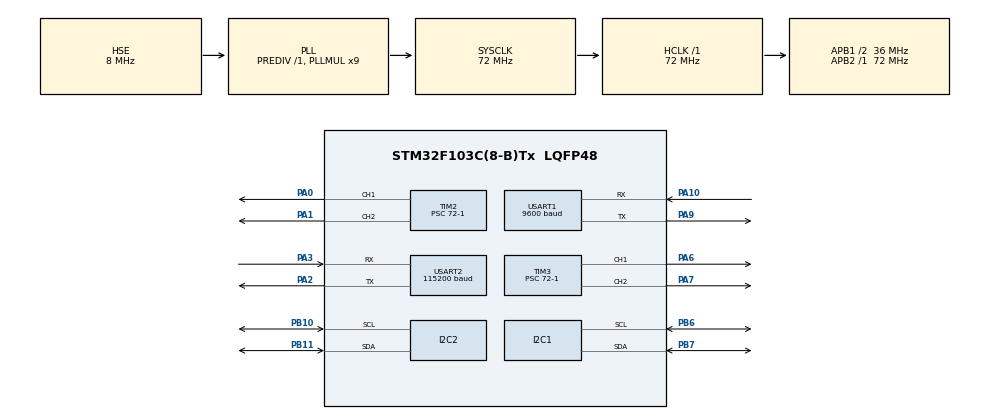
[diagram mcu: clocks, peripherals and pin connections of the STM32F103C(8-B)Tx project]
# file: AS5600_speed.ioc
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Dma.I2C1_RX.0.Direction=DMA_PERIPH_TO_MEMORY
Dma.I2C1_RX.0.Instance=DMA1_Channel7
Dma.I2C1_RX.0.MemDataAlignment=DMA_MDATAALIGN_BYTE
Dma.I2C1_RX.0.MemInc=DMA_MINC_ENABLE
Dma.I2C1_RX.0.Mode=DMA_NORMAL
Dma.I2C1_RX.0.PeriphDataAlignment=DMA_PDATAALIGN_BYTE
Dma.I2C1_RX.0.PeriphInc=DMA_PINC_DISABLE
Dma.I2C1_RX.0.Priority=DMA_PRIORITY_LOW
Dma.I2C2_RX.1.Direction=DMA_PERIPH_TO_MEMORY
Dma.I2C2_RX.1.Instance=DMA1_Channel5
Dma.I2C2_RX.1.MemDataAlignment=DMA_MDATAALIGN_BYTE
Dma.I2C2_RX.1.MemInc=DMA_MINC_ENABLE
Dma.I2C2_RX.1.Mode=DMA_NORMAL
Dma.I2C2_RX.1.PeriphDataAlignment=DMA_PDATAALIGN_BYTE
Dma.I2C2_RX.1.PeriphInc=DMA_PINC_DISABLE
Dma.I2C2_RX.1.Priority=DMA_PRIORITY_LOW
Dma.Request0=I2C1_RX
Dma.Request1=I2C2_RX
FREERTOS.Tasks01=defaultTask,0,128,StartDefaultTask,As weak,NULL,Dynamic,NULL,NULL;myTask02,0,128,Motor_Task,As weak,NULL,Dynamic,NULL,NULL
I2C1.I2C_Mode=I2C_Fast
I2C2.I2C_Mode=I2C_Fast
Mcu.Family=STM32F1
Mcu.Name=STM32F103C(8-B)Tx
Mcu.Package=LQFP48
NVIC.DMA1_Channel5_IRQn=true\:5\:0\:false\:false\:true\:true\:false\:true\:true
NVIC.DMA1_Channel7_IRQn=true\:5\:0\:false\:false\:true\:true\:false\:true\:true
NVIC.PriorityGroup=NVIC_PRIORITYGROUP_4
NVIC.TIM4_IRQn=true\:5\:0\:false\:false\:true\:true\:true\:true\:true
NVIC.USART1_IRQn=true\:5\:0\:false\:false\:true\:true\:true\:true\:true
NVIC.USART2_IRQn=true\:5\:0\:false\:false\:true\:true\:true\:true\:true
PA0-WKUP.Signal=S_TIM2_CH1_ETR
PA1.Signal=S_TIM2_CH2
PA10.Mode=Asynchronous
PA10.Signal=USART1_RX
PA13.Mode=Serial_Wire
PA13.Signal=SYS_JTMS-SWDIO
PA14.Mode=Serial_Wire
PA14.Signal=SYS_JTCK-SWCLK
PA2.Mode=Asynchronous
PA2.Signal=USART2_TX
PA3.Mode=Asynchronous
PA3.Signal=USART2_RX
PA6.Signal=S_TIM3_CH1
PA7.Signal=S_TIM3_CH2
PA9.Mode=Asynchronous
PA9.Signal=USART1_TX
PB10.Mode=I2C
PB10.Signal=I2C2_SCL
PB11.Mode=I2C
PB11.Signal=I2C2_SDA
PB6.Mode=I2C
PB6.Signal=I2C1_SCL
PB7.Mode=I2C
PB7.Signal=I2C1_SDA
PD0-OSC_IN.Mode=HSE-External-Oscillator
PD0-OSC_IN.Signal=RCC_OSC_IN
PD1-OSC_OUT.Mode=HSE-External-Oscillator
PD1-OSC_OUT.Signal=RCC_OSC_OUT
ProjectManager.HeapSize=0x200
ProjectManager.StackSize=0x400
ProjectManager.TargetToolchain=MDK-ARM V5.32
RCC.AHBFreq_Value=72000000
RCC.APB1CLKDivider=RCC_HCLK_DIV2
RCC.APB1Freq_Value=36000000
RCC.APB1TimFreq_Value=72000000
RCC.APB2Freq_Value=72000000
RCC.APB2TimFreq_Value=72000000
RCC.HCLKFreq_Value=72000000
RCC.PLLMUL=RCC_PLL_MUL9
RCC.PLLSourceVirtual=RCC_PLLSOURCE_HSE
RCC.SYSCLKFreq_VALUE=72000000
RCC.SYSCLKSource=RCC_SYSCLKSOURCE_PLLCLK
RCC.USBFreq_Value=72000000
SH.S_TIM2_CH1_ETR.0=TIM2_CH1,PWM Generation1 CH1
SH.S_TIM2_CH2.0=TIM2_CH2,PWM Generation2 CH2
SH.S_TIM3_CH1.0=TIM3_CH1,PWM Generation1 CH1
SH.S_TIM3_CH2.0=TIM3_CH2,PWM Generation2 CH2
TIM2.Channel-PWM\ Generation1\ CH1=TIM_CHANNEL_1
TIM2.Channel-PWM\ Generation2\ CH2=TIM_CHANNEL_2
TIM2.Period=20000-1
TIM2.Prescaler=72-1
TIM3.Channel-PWM\ Generation1\ CH1=TIM_CHANNEL_1
TIM3.Channel-PWM\ Generation2\ CH2=TIM_CHANNEL_2
TIM3.Period=20000-1
TIM3.Prescaler=72-1
TIM4.Period=10-1
TIM4.Prescaler=7200-1
USART1.BaudRate=9600
USART1.VirtualMode=VM_ASYNC
USART2.BaudRate=115200
USART2.VirtualMode=VM_ASYNC
VP_FREERTOS_VS_CMSIS_V1.Mode=CMSIS_V1
VP_TIM4_VS_ClockSourceINT.Mode=Internal
board=custom

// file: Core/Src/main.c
/* USER CODE BEGIN Header */
/**
  ******************************************************************************
  * @file           : main.c
  * @brief          : Main program body
  ******************************************************************************
  * @attention
  *
  * Copyright (c) 2025 STMicroelectronics.
  * All rights reserved.
  *
  * This software is licensed under terms that can be found in the LICENSE file
  * in the root directory of this software component.
  * If no LICENSE file comes with this software, it is provided AS-IS.
  *
  ******************************************************************************
  */
/* USER CODE END Header */
#include "main.h"
#include "cmsis_os.h"
#include "dma.h"
#include "i2c.h"
#include "tim.h"
#include "usart.h"
#include "gpio.h"

/* USER CODE BEGIN PTD */
#include "MT6701.h"
/* USER CODE END PTD */

void SystemClock_Config(void);
void MX_FREERTOS_Init(void);
/* USER CODE BEGIN PFP */
extern uint8_t rx_buffer[1];
/* USER CODE END PFP */

int main(void)
{

  /* MCU Configuration--------------------------------------------------------*/

  /* Reset of all peripherals, Initializes the Flash interface and the Systick. */
  HAL_Init();

  /* Configure the system clock */
  SystemClock_Config();

  /* Initialize all configured peripherals */
  MX_GPIO_Init();
  MX_DMA_Init();
  MX_I2C2_Init();
  MX_TIM2_Init();
  MX_I2C1_Init();
  MX_TIM3_Init();
  MX_USART1_UART_Init();
  MX_USART2_UART_Init();
  MX_TIM4_Init();
  /* USER CODE BEGIN 2 */

  // Motor_PWM_Init(&htim3);

  /* USER CODE END 2 */

  /* Call init function for freertos objects (in cmsis_os2.c) */
  MX_FREERTOS_Init();

  /* Start scheduler */
  osKernelStart();

  /* We should never get here as control is now taken by the scheduler */

  /* Infinite loop */
  /* USER CODE BEGIN WHILE */
  while (1)
  {
    // N5065_Data.angle=AS5600_ReadAngle( );
    // N5065_Data.speed_rpm = low_pass_filter(calculate_rpm());

    /* USER CODE END WHILE */

  }
}

void SystemClock_Config(void)
{
  RCC_OscInitTypeDef RCC_OscInitStruct = {0};
  RCC_ClkInitTypeDef RCC_ClkInitStruct = {0};

  /** Initializes the RCC Oscillators according to the specified parameters
  * in the RCC_OscInitTypeDef structure.
  */
  RCC_OscInitStruct.OscillatorType = RCC_OSCILLATORTYPE_HSE;
  RCC_OscInitStruct.HSEState = RCC_HSE_ON;
  RCC_OscInitStruct.HSEPredivValue = RCC_HSE_PREDIV_DIV1;
  RCC_OscInitStruct.HSIState = RCC_HSI_ON;
  RCC_OscInitStruct.PLL.PLLState = RCC_PLL_ON;
  RCC_OscInitStruct.PLL.PLLSource = RCC_PLLSOURCE_HSE;
  RCC_OscInitStruct.PLL.PLLMUL = RCC_PLL_MUL9;
  if (HAL_RCC_OscConfig(&RCC_OscInitStruct) != HAL_OK)
  {
    Error_Handler();
  }

  /** Initializes the CPU, AHB and APB buses clocks
  */
  RCC_ClkInitStruct.ClockType = RCC_CLOCKTYPE_HCLK|RCC_CLOCKTYPE_SYSCLK
                              |RCC_CLOCKTYPE_PCLK1|RCC_CLOCKTYPE_PCLK2;
  RCC_ClkInitStruct.SYSCLKSource = RCC_SYSCLKSOURCE_PLLCLK;
  RCC_ClkInitStruct.AHBCLKDivider = RCC_SYSCLK_DIV1;
  RCC_ClkInitStruct.APB1CLKDivider = RCC_HCLK_DIV2;
  RCC_ClkInitStruct.APB2CLKDivider = RCC_HCLK_DIV1;

  if (HAL_RCC_ClockConfig(&RCC_ClkInitStruct, FLASH_LATENCY_2) != HAL_OK)
  {
    Error_Handler();
  }
}

void Error_Handler(void)
{
  __disable_irq();
  while (1)
  {
  }
}

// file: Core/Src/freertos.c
/* USER CODE BEGIN Header */
/**
  ******************************************************************************
  * File Name          : freertos.c
  * Description        : Code for freertos applications
  ******************************************************************************
  * @attention
  *
  * Copyright (c) 2025 STMicroelectronics.
  * All rights reserved.
  *
  * This software is licensed under terms that can be found in the LICENSE file
  * in the root directory of this software component.
  * If no LICENSE file comes with this software, it is provided AS-IS.
  *
  ******************************************************************************
  */
/* USER CODE END Header */

#include "FreeRTOS.h"
#include "task.h"
#include "main.h"
#include "cmsis_os.h"

osThreadId defaultTaskHandle;
osThreadId myTask02Handle;

void StartDefaultTask(void const * argument);
void Motor_Task(void const * argument);

void MX_FREERTOS_Init(void); /* (MISRA C 2004 rule 8.1) */

/* GetIdleTaskMemory prototype (linked to static allocation support) */
void vApplicationGetIdleTaskMemory( StaticTask_t **ppxIdleTaskTCBBuffer, StackType_t **ppxIdleTaskStackBuffer, uint32_t *pulIdleTaskStackSize );

/* USER CODE BEGIN GET_IDLE_TASK_MEMORY */
static StaticTask_t xIdleTaskTCBBuffer;
static StackType_t xIdleStack[configMINIMAL_STACK_SIZE];

void vApplicationGetIdleTaskMemory( StaticTask_t **ppxIdleTaskTCBBuffer, StackType_t **ppxIdleTaskStackBuffer, uint32_t *pulIdleTaskStackSize )
{
  *ppxIdleTaskTCBBuffer = &xIdleTaskTCBBuffer;
  *ppxIdleTaskStackBuffer = &xIdleStack[0];
  *pulIdleTaskStackSize = configMINIMAL_STACK_SIZE;
  /* place for user code */
}
/* USER CODE END GET_IDLE_TASK_MEMORY */

void MX_FREERTOS_Init(void) {

  /* Create the thread(s) */
  /* definition and creation of defaultTask */
  osThreadDef(defaultTask, StartDefaultTask, osPriorityNormal, 0, 128);
  defaultTaskHandle = osThreadCreate(osThread(defaultTask), NULL);

  /* definition and creation of myTask02 */
  osThreadDef(myTask02, Motor_Task, osPriorityNormal, 0, 128);
  myTask02Handle = osThreadCreate(osThread(myTask02), NULL);

}

__weak void StartDefaultTask(void const * argument)
{
  for(;;)
  {
    osDelay(1);
  }
}

__weak void Motor_Task(void const * argument)
{
  for(;;)
  {
    osDelay(1);
  }
}
